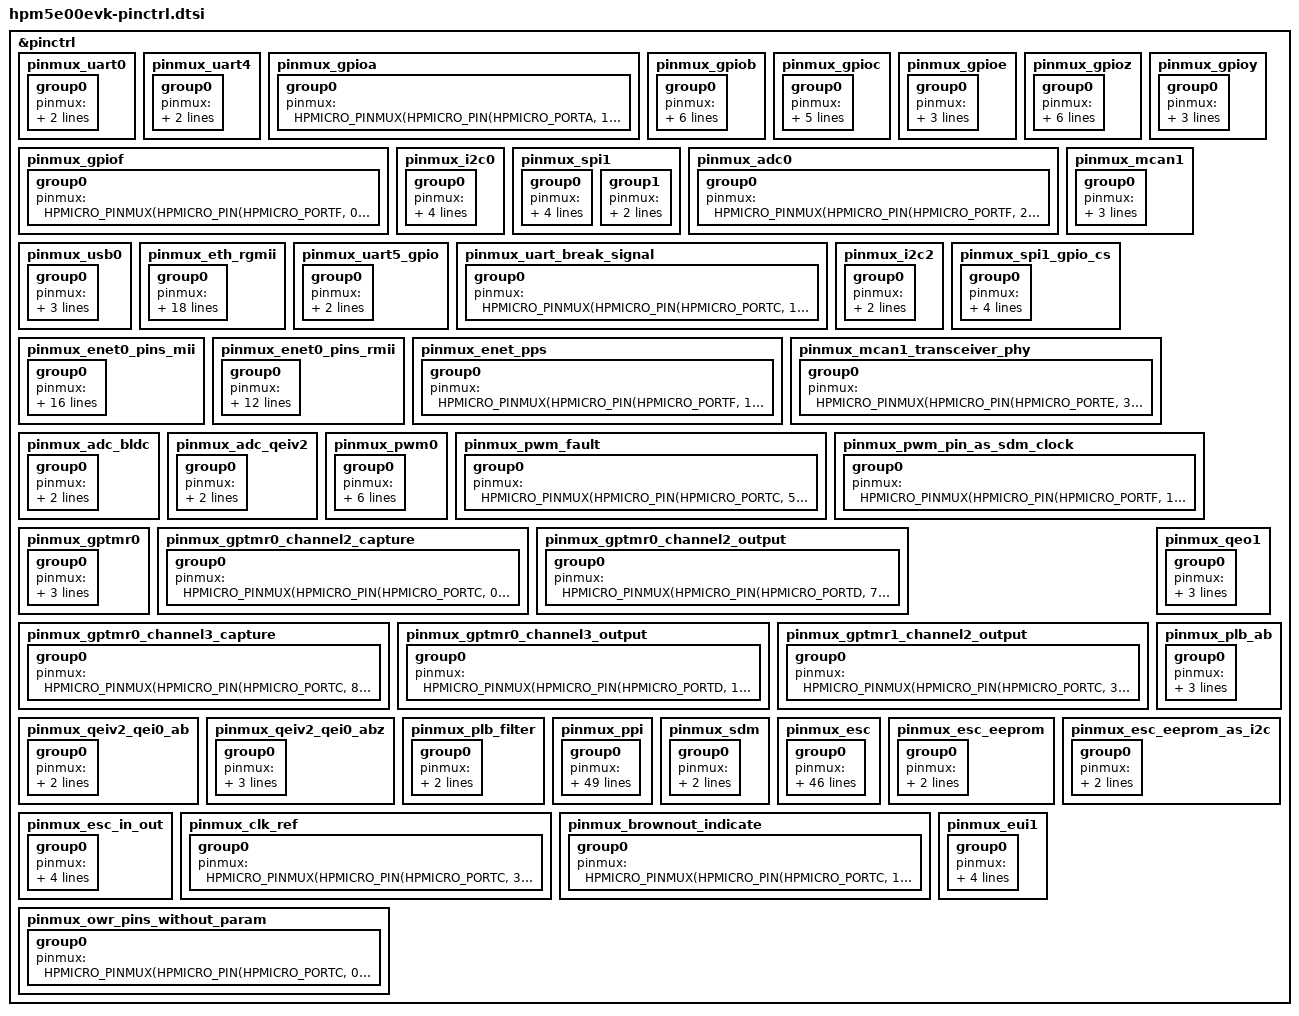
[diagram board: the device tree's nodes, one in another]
/*
* Copyright (c) 2026 HPMicro
* SPDX-License-Identifier: Apache-2.0
*/

#include "dt-bindings/pinctrl/hpmicro-pinctrl-common.h"

&pinctrl {
	pinmux_uart0: pinmux_uart0 {
		group0 {
			pinmux = <HPMICRO_PINMUX(HPMICRO_PIN(HPMICRO_PORTA, 0), IOC_TYPE_IOC, 0, 2)>,
				<HPMICRO_PINMUX(HPMICRO_PIN(HPMICRO_PORTA, 1), IOC_TYPE_IOC, 0, 2)>;
		};
	};

	pinmux_uart4: pinmux_uart4 {
		group0 {
			pinmux = <HPMICRO_PINMUX(HPMICRO_PIN(HPMICRO_PORTC, 16), IOC_TYPE_IOC, 0, 2)>,
				<HPMICRO_PINMUX(HPMICRO_PIN(HPMICRO_PORTC, 17), IOC_TYPE_IOC, 0, 2)>;
		};
	};

	pinmux_gpioa: pinmux_gpioa {
		group0 {
			pinmux = <HPMICRO_PINMUX(HPMICRO_PIN(HPMICRO_PORTA, 14), IOC_TYPE_IOC, 0, 0)>;
		};
	};

	pinmux_gpiob: pinmux_gpiob {
		group0 {
			pinmux = <HPMICRO_PINMUX(HPMICRO_PIN(HPMICRO_PORTB, 11), IOC_TYPE_IOC, 0, 0)>,
				<HPMICRO_PINMUX(HPMICRO_PIN(HPMICRO_PORTB, 12), IOC_TYPE_IOC, 0, 0)>,
				<HPMICRO_PINMUX(HPMICRO_PIN(HPMICRO_PORTB, 13), IOC_TYPE_IOC, 0, 0)>,
				<HPMICRO_PINMUX(HPMICRO_PIN(HPMICRO_PORTB, 8), IOC_TYPE_IOC, 0, 0)>,
				<HPMICRO_PINMUX(HPMICRO_PIN(HPMICRO_PORTB, 9), IOC_TYPE_IOC, 0, 0)>;
			bias-pull-down;
		};
	};

	pinmux_gpioc: pinmux_gpioc {
		group0 {
			pinmux = <HPMICRO_PINMUX(HPMICRO_PIN(HPMICRO_PORTC, 21), IOC_TYPE_IOC, 0, 0)>;
			bias-pull-up;
			input-enable;
			keeper-capability-disable;
			input-schmitt-enable;
		};
	};

	pinmux_gpioe: pinmux_gpioe {
		group0 {
			pinmux = <HPMICRO_PINMUX(HPMICRO_PIN(HPMICRO_PORTE, 4), IOC_TYPE_IOC, 0, 0)>,
				<HPMICRO_PINMUX(HPMICRO_PIN(HPMICRO_PORTE, 14), IOC_TYPE_IOC, 0, 0)>,
				<HPMICRO_PINMUX(HPMICRO_PIN(HPMICRO_PORTE, 15), IOC_TYPE_IOC, 0, 0)>;
		};
	};

	pinmux_gpiof: pinmux_gpiof {
		group0 {
			pinmux = <HPMICRO_PINMUX(HPMICRO_PIN(HPMICRO_PORTF, 0), IOC_TYPE_IOC, 0, 0)>;
		};
	};

	pinmux_gpioz: pinmux_gpioz {
		group0 {
			pinmux = <HPMICRO_PINMUX(HPMICRO_PIN(HPMICRO_PORTZ, 2), IOC_TYPE_IOC, 0, 0)>,
				<HPMICRO_PINMUX(HPMICRO_PIN(HPMICRO_PORTZ, 2), IOC_TYPE_BIOC, 0, 3)>,
				<HPMICRO_PINMUX(HPMICRO_PIN(HPMICRO_PORTZ, 3), IOC_TYPE_IOC, 0, 0)>,
				<HPMICRO_PINMUX(HPMICRO_PIN(HPMICRO_PORTZ, 3), IOC_TYPE_BIOC, 0, 3)>;
			bias-pull-up;
			input-enable;
		};
	};

	pinmux_gpioy: pinmux_gpioy {
		group0 {
			pinmux = <HPMICRO_PINMUX(HPMICRO_PIN(HPMICRO_PORTY, 5), IOC_TYPE_IOC, 0, 0)>,
				<HPMICRO_PINMUX(HPMICRO_PIN(HPMICRO_PORTY, 5), IOC_TYPE_BIOC, 0, 3)>;
			bias-pull-up;
		};
	};

	pinmux_i2c0: pinmux_i2c0 {
		group0 {
			pinmux = <HPMICRO_PINMUX(HPMICRO_PIN(HPMICRO_PORTC, 8), IOC_TYPE_IOC, 0, 4)>,
				<HPMICRO_PINMUX(HPMICRO_PIN(HPMICRO_PORTC, 9), IOC_TYPE_IOC, 0, 4)>;
			drive-open-drain;
			input-enable;
		};
	};

	pinmux_spi1: pinmux_spi1 {
		group0 {
			pinmux = <HPMICRO_PINMUX(HPMICRO_PIN(HPMICRO_PORTC, 10), IOC_TYPE_IOC, 0, 5)>,
				<HPMICRO_PINMUX(HPMICRO_PIN(HPMICRO_PORTC, 12), IOC_TYPE_IOC, 0, 5)>,
				<HPMICRO_PINMUX(HPMICRO_PIN(HPMICRO_PORTC, 13), IOC_TYPE_IOC, 0, 5)>;
			input-enable;
		};

		group1 {
			pinmux = <HPMICRO_PINMUX(HPMICRO_PIN(HPMICRO_PORTC, 11), IOC_TYPE_IOC, 0, 0)>;
			bias-pull-up;
		};
	};

	pinmux_adc0: pinmux_adc0 {
		group0 {
			pinmux = <HPMICRO_PINMUX(HPMICRO_PIN(HPMICRO_PORTF, 26), IOC_TYPE_IOC, 1, 0)>;
		};
	};

	pinmux_mcan1: pinmux_mcan1 {
		group0 {
			pinmux = <HPMICRO_PINMUX(HPMICRO_PIN(HPMICRO_PORTE, 5), IOC_TYPE_IOC, 0, 7)>,
				<HPMICRO_PINMUX(HPMICRO_PIN(HPMICRO_PORTE, 4), IOC_TYPE_IOC, 0, 7)>,
				<HPMICRO_PINMUX(HPMICRO_PIN(HPMICRO_PORTE, 3), IOC_TYPE_IOC, 0, 7)>;
		};
	};

	pinmux_usb0: pinmux_usb0 {
		group0 {
			pinmux = <HPMICRO_PINMUX(HPMICRO_PIN(HPMICRO_PORTF, 19), IOC_TYPE_IOC, 0, 24)>,
				<HPMICRO_PINMUX(HPMICRO_PIN(HPMICRO_PORTF, 22), IOC_TYPE_IOC, 0, 24)>,
				<HPMICRO_PINMUX(HPMICRO_PIN(HPMICRO_PORTF, 23), IOC_TYPE_IOC, 0, 24)>;
		};
	};

	pinmux_eth_rgmii: pinmux_eth_rgmii {
		group0 {
			pinmux = <HPMICRO_PINMUX(HPMICRO_PIN(HPMICRO_PORTF, 1), IOC_TYPE_IOC, 0, 18)>,
				<HPMICRO_PINMUX(HPMICRO_PIN(HPMICRO_PORTF, 0), IOC_TYPE_IOC, 0, 18)>,
				<HPMICRO_PINMUX(HPMICRO_PIN(HPMICRO_PORTB, 0), IOC_TYPE_IOC, 0, 18)>,
				<HPMICRO_PINMUX(HPMICRO_PIN(HPMICRO_PORTB, 1), IOC_TYPE_IOC, 0, 18)>,
				<HPMICRO_PINMUX(HPMICRO_PIN(HPMICRO_PORTB, 2), IOC_TYPE_IOC, 0, 18)>,
				<HPMICRO_PINMUX(HPMICRO_PIN(HPMICRO_PORTB, 3), IOC_TYPE_IOC, 0, 18)>,
				<HPMICRO_PINMUX(HPMICRO_PIN(HPMICRO_PORTB, 4), IOC_TYPE_IOC, 0, 18)>,
				<HPMICRO_PINMUX(HPMICRO_PIN(HPMICRO_PORTB, 5), IOC_TYPE_IOC, 0, 18)>,
				<HPMICRO_PINMUX(HPMICRO_PIN(HPMICRO_PORTB, 6), IOC_TYPE_IOC, 0, 18)>,
				<HPMICRO_PINMUX(HPMICRO_PIN(HPMICRO_PORTB, 7), IOC_TYPE_IOC, 0, 18)>,
				<HPMICRO_PINMUX(HPMICRO_PIN(HPMICRO_PORTB, 8), IOC_TYPE_IOC, 0, 18)>,
				<HPMICRO_PINMUX(HPMICRO_PIN(HPMICRO_PORTB, 9), IOC_TYPE_IOC, 0, 18)>,
				<HPMICRO_PINMUX(HPMICRO_PIN(HPMICRO_PORTB, 10), IOC_TYPE_IOC, 0, 18)>,
				<HPMICRO_PINMUX(HPMICRO_PIN(HPMICRO_PORTB, 11), IOC_TYPE_IOC, 0, 18)>;
			input-schmitt-enable;
			slew-rate = "fast";
			slew-pd = "100M";
			drive-strength = "r011";
		};
	};

	pinmux_uart5_gpio: pinmux_uart5_gpio {
		group0 {
			pinmux = <HPMICRO_PINMUX(HPMICRO_PIN(HPMICRO_PORTC, 22), IOC_TYPE_IOC, 0, 0)>,
				<HPMICRO_PINMUX(HPMICRO_PIN(HPMICRO_PORTC, 23), IOC_TYPE_IOC, 0, 0)>;
		};
	};

	pinmux_uart_break_signal: pinmux_uart_break_signal {
		group0 {
			pinmux = <HPMICRO_PINMUX(HPMICRO_PIN(HPMICRO_PORTC, 11), IOC_TYPE_IOC, 0, 0)>;
		};
	};

	pinmux_i2c2: pinmux_i2c2 {
		group0 {
			pinmux = <HPMICRO_PINMUX(HPMICRO_PIN(HPMICRO_PORTD, 3), IOC_TYPE_IOC, 0, 4)>,
				<HPMICRO_PINMUX(HPMICRO_PIN(HPMICRO_PORTD, 2), IOC_TYPE_IOC, 0, 4)>;
		};
	};

	pinmux_spi1_gpio_cs: pinmux_spi1_gpio_cs {
		group0 {
			pinmux = <HPMICRO_PINMUX(HPMICRO_PIN(HPMICRO_PORTC, 11), IOC_TYPE_IOC, 0, 0)>,
				<HPMICRO_PINMUX(HPMICRO_PIN(HPMICRO_PORTC, 10), IOC_TYPE_IOC, 0, 5)>,
				<HPMICRO_PINMUX(HPMICRO_PIN(HPMICRO_PORTC, 12), IOC_TYPE_IOC, 0, 5)>,
				<HPMICRO_PINMUX(HPMICRO_PIN(HPMICRO_PORTC, 13), IOC_TYPE_IOC, 0, 5)>;
		};
	};

	pinmux_enet0_pins_mii: pinmux_enet0_pins_mii {
		group0 {
			pinmux = <HPMICRO_PINMUX(HPMICRO_PIN(HPMICRO_PORTA, 9), IOC_TYPE_IOC, 0, 11)>,
				<HPMICRO_PINMUX(HPMICRO_PIN(HPMICRO_PORTB, 24), IOC_TYPE_IOC, 0, 0)>,
				<HPMICRO_PINMUX(HPMICRO_PIN(HPMICRO_PORTA, 30), IOC_TYPE_IOC, 0, 18)>,
				<HPMICRO_PINMUX(HPMICRO_PIN(HPMICRO_PORTA, 31), IOC_TYPE_IOC, 0, 18)>,
				<HPMICRO_PINMUX(HPMICRO_PIN(HPMICRO_PORTF, 2), IOC_TYPE_IOC, 0, 18)>,
				<HPMICRO_PINMUX(HPMICRO_PIN(HPMICRO_PORTF, 3), IOC_TYPE_IOC, 0, 18)>,
				<HPMICRO_PINMUX(HPMICRO_PIN(HPMICRO_PORTF, 4), IOC_TYPE_IOC, 0, 18)>,
				<HPMICRO_PINMUX(HPMICRO_PIN(HPMICRO_PORTF, 5), IOC_TYPE_IOC, 0, 18)>,
				<HPMICRO_PINMUX(HPMICRO_PIN(HPMICRO_PORTF, 6), IOC_TYPE_IOC, 0, 18)>,
				<HPMICRO_PINMUX(HPMICRO_PIN(HPMICRO_PORTF, 7), IOC_TYPE_IOC, 0, 18)>,
				<HPMICRO_PINMUX(HPMICRO_PIN(HPMICRO_PORTF, 8), IOC_TYPE_IOC, 0, 18)>,
				<HPMICRO_PINMUX(HPMICRO_PIN(HPMICRO_PORTF, 9), IOC_TYPE_IOC, 0, 18)>,
				<HPMICRO_PINMUX(HPMICRO_PIN(HPMICRO_PORTF, 10), IOC_TYPE_IOC, 0, 18)>,
				<HPMICRO_PINMUX(HPMICRO_PIN(HPMICRO_PORTF, 11), IOC_TYPE_IOC, 0, 18)>,
				<HPMICRO_PINMUX(HPMICRO_PIN(HPMICRO_PORTF, 12), IOC_TYPE_IOC, 0, 18)>,
				<HPMICRO_PINMUX(HPMICRO_PIN(HPMICRO_PORTF, 13), IOC_TYPE_IOC, 0, 18)>;
		};
	};

	pinmux_enet0_pins_rmii: pinmux_enet0_pins_rmii {
		group0 {
			pinmux = <HPMICRO_PINMUX(HPMICRO_PIN(HPMICRO_PORTA, 9), IOC_TYPE_IOC, 0, 11)>,
				<HPMICRO_PINMUX(HPMICRO_PIN(HPMICRO_PORTB, 24), IOC_TYPE_IOC, 0, 0)>,
				<HPMICRO_PINMUX(HPMICRO_PIN(HPMICRO_PORTF, 2), IOC_TYPE_IOC, 0, 18)>,
				<HPMICRO_PINMUX(HPMICRO_PIN(HPMICRO_PORTA, 30), IOC_TYPE_IOC, 0, 18)>,
				<HPMICRO_PINMUX(HPMICRO_PIN(HPMICRO_PORTA, 31), IOC_TYPE_IOC, 0, 18)>,
				<HPMICRO_PINMUX(HPMICRO_PIN(HPMICRO_PORTF, 3), IOC_TYPE_IOC, 0, 18)>,
				<HPMICRO_PINMUX(HPMICRO_PIN(HPMICRO_PORTF, 4), IOC_TYPE_IOC, 0, 18)>,
				<HPMICRO_PINMUX(HPMICRO_PIN(HPMICRO_PORTF, 7), IOC_TYPE_IOC, 0, 18)>,
				<HPMICRO_PINMUX(HPMICRO_PIN(HPMICRO_PORTF, 8), IOC_TYPE_IOC, 0, 18)>,
				<HPMICRO_PINMUX(HPMICRO_PIN(HPMICRO_PORTF, 9), IOC_TYPE_IOC, 0, 18)>,
				<HPMICRO_PINMUX(HPMICRO_PIN(HPMICRO_PORTF, 10), IOC_TYPE_IOC, 0, 18)>;
			input-enable;
		};
	};

	pinmux_enet_pps: pinmux_enet_pps {
		group0 {
			pinmux = <HPMICRO_PINMUX(HPMICRO_PIN(HPMICRO_PORTF, 18), IOC_TYPE_IOC, 0, 25)>;
		};
	};

	pinmux_mcan1_transceiver_phy: pinmux_mcan1_transceiver_phy {
		group0 {
			pinmux = <HPMICRO_PINMUX(HPMICRO_PIN(HPMICRO_PORTE, 3), IOC_TYPE_IOC, 0, 0)>;
		};
	};

	pinmux_adc_bldc: pinmux_adc_bldc {
		group0 {
			pinmux = <HPMICRO_PINMUX(HPMICRO_PIN(HPMICRO_PORTF, 28), IOC_TYPE_IOC, 1, 0)>,
				<HPMICRO_PINMUX(HPMICRO_PIN(HPMICRO_PORTF, 29), IOC_TYPE_IOC, 1, 0)>;
		};
	};

	pinmux_adc_qeiv2: pinmux_adc_qeiv2 {
		group0 {
			pinmux = <HPMICRO_PINMUX(HPMICRO_PIN(HPMICRO_PORTF, 30), IOC_TYPE_IOC, 1, 0)>,
				<HPMICRO_PINMUX(HPMICRO_PIN(HPMICRO_PORTF, 28), IOC_TYPE_IOC, 1, 0)>;
		};
	};

	pinmux_pwm0: pinmux_pwm0 {
		group0 {
			pinmux = <HPMICRO_PINMUX(HPMICRO_PIN(HPMICRO_PORTD, 0), IOC_TYPE_IOC, 0, 16)>,
				<HPMICRO_PINMUX(HPMICRO_PIN(HPMICRO_PORTD, 1), IOC_TYPE_IOC, 0, 16)>,
				<HPMICRO_PINMUX(HPMICRO_PIN(HPMICRO_PORTD, 2), IOC_TYPE_IOC, 0, 16)>,
				<HPMICRO_PINMUX(HPMICRO_PIN(HPMICRO_PORTD, 3), IOC_TYPE_IOC, 0, 16)>,
				<HPMICRO_PINMUX(HPMICRO_PIN(HPMICRO_PORTD, 4), IOC_TYPE_IOC, 0, 16)>,
				<HPMICRO_PINMUX(HPMICRO_PIN(HPMICRO_PORTD, 5), IOC_TYPE_IOC, 0, 16)>;
		};
	};

	pinmux_pwm_fault: pinmux_pwm_fault {
		group0 {
			pinmux = <HPMICRO_PINMUX(HPMICRO_PIN(HPMICRO_PORTC, 5), IOC_TYPE_IOC, 0, 17)>;
		};
	};

	pinmux_pwm_pin_as_sdm_clock: pinmux_pwm_pin_as_sdm_clock {
		group0 {
			pinmux = <HPMICRO_PINMUX(HPMICRO_PIN(HPMICRO_PORTF, 15), IOC_TYPE_IOC, 0, 16)>;
		};
	};

	pinmux_gptmr0: pinmux_gptmr0 {
		group0 {
			pinmux = <HPMICRO_PINMUX(HPMICRO_PIN(HPMICRO_PORTC, 0), IOC_TYPE_IOC, 0, 17)>,
				<HPMICRO_PINMUX(HPMICRO_PIN(HPMICRO_PORTD, 7), IOC_TYPE_IOC, 0, 17)>,
				<HPMICRO_PINMUX(HPMICRO_PIN(HPMICRO_PORTD, 15), IOC_TYPE_IOC, 0, 17)>;
		};
	};

	pinmux_gptmr0_channel2_capture: pinmux_gptmr0_channel2_capture {
		group0 {
			pinmux = <HPMICRO_PINMUX(HPMICRO_PIN(HPMICRO_PORTC, 0), IOC_TYPE_IOC, 0, 17)>;
		};
	};

	pinmux_gptmr0_channel2_output: pinmux_gptmr0_channel2_output {
		group0 {
			pinmux = <HPMICRO_PINMUX(HPMICRO_PIN(HPMICRO_PORTD, 7), IOC_TYPE_IOC, 0, 17)>;
		};
	};

	pinmux_gptmr0_channel3_capture: pinmux_gptmr0_channel3_capture {
		group0 {
			pinmux = <HPMICRO_PINMUX(HPMICRO_PIN(HPMICRO_PORTC, 8), IOC_TYPE_IOC, 0, 17)>;
		};
	};

	pinmux_gptmr0_channel3_output: pinmux_gptmr0_channel3_output {
		group0 {
			pinmux = <HPMICRO_PINMUX(HPMICRO_PIN(HPMICRO_PORTD, 15), IOC_TYPE_IOC, 0, 17)>;
		};
	};

	pinmux_gptmr1_channel2_output: pinmux_gptmr1_channel2_output {
		group0 {
			pinmux = <HPMICRO_PINMUX(HPMICRO_PIN(HPMICRO_PORTC, 3), IOC_TYPE_IOC, 0, 17)>;
		};
	};

	pinmux_qeo1: pinmux_qeo1 {
		group0 {
			pinmux = <HPMICRO_PINMUX(HPMICRO_PIN(HPMICRO_PORTC, 12), IOC_TYPE_IOC, 0, 21)>,
				<HPMICRO_PINMUX(HPMICRO_PIN(HPMICRO_PORTC, 13), IOC_TYPE_IOC, 0, 21)>,
				<HPMICRO_PINMUX(HPMICRO_PIN(HPMICRO_PORTC, 14), IOC_TYPE_IOC, 0, 21)>;
		};
	};

	pinmux_qeiv2_qei0_ab: pinmux_qeiv2_qei0_ab {
		group0 {
			pinmux = <HPMICRO_PINMUX(HPMICRO_PIN(HPMICRO_PORTC, 7), IOC_TYPE_IOC, 0, 20)>,
				<HPMICRO_PINMUX(HPMICRO_PIN(HPMICRO_PORTC, 6), IOC_TYPE_IOC, 0, 20)>;
		};
	};

	pinmux_qeiv2_qei0_abz: pinmux_qeiv2_qei0_abz {
		group0 {
			pinmux = <HPMICRO_PINMUX(HPMICRO_PIN(HPMICRO_PORTC, 7), IOC_TYPE_IOC, 0, 20)>,
				<HPMICRO_PINMUX(HPMICRO_PIN(HPMICRO_PORTC, 6), IOC_TYPE_IOC, 0, 20)>,
				<HPMICRO_PINMUX(HPMICRO_PIN(HPMICRO_PORTC, 5), IOC_TYPE_IOC, 0, 20)>;
		};
	};

	pinmux_plb_ab: pinmux_plb_ab {
		group0 {
			pinmux = <HPMICRO_PINMUX(HPMICRO_PIN(HPMICRO_PORTC, 5), IOC_TYPE_IOC, 0, 17)>,
				<HPMICRO_PINMUX(HPMICRO_PIN(HPMICRO_PORTC, 6), IOC_TYPE_IOC, 0, 17)>,
				<HPMICRO_PINMUX(HPMICRO_PIN(HPMICRO_PORTC, 7), IOC_TYPE_IOC, 0, 17)>;
		};
	};

	pinmux_plb_filter: pinmux_plb_filter {
		group0 {
			pinmux = <HPMICRO_PINMUX(HPMICRO_PIN(HPMICRO_PORTD, 2), IOC_TYPE_IOC, 0, 17)>,
				<HPMICRO_PINMUX(HPMICRO_PIN(HPMICRO_PORTD, 4), IOC_TYPE_IOC, 0, 17)>;
		};
	};

	pinmux_ppi: pinmux_ppi {
		group0 {
			pinmux = <HPMICRO_PINMUX(HPMICRO_PIN(HPMICRO_PORTD, 31), IOC_TYPE_IOC, 0, 13)>,
				<HPMICRO_PINMUX(HPMICRO_PIN(HPMICRO_PORTD, 30), IOC_TYPE_IOC, 0, 13)>,
				<HPMICRO_PINMUX(HPMICRO_PIN(HPMICRO_PORTD, 29), IOC_TYPE_IOC, 0, 13)>,
				<HPMICRO_PINMUX(HPMICRO_PIN(HPMICRO_PORTD, 28), IOC_TYPE_IOC, 0, 13)>,
				<HPMICRO_PINMUX(HPMICRO_PIN(HPMICRO_PORTD, 27), IOC_TYPE_IOC, 0, 13)>,
				<HPMICRO_PINMUX(HPMICRO_PIN(HPMICRO_PORTD, 26), IOC_TYPE_IOC, 0, 13)>,
				<HPMICRO_PINMUX(HPMICRO_PIN(HPMICRO_PORTD, 24), IOC_TYPE_IOC, 0, 13)>,
				<HPMICRO_PINMUX(HPMICRO_PIN(HPMICRO_PORTD, 25), IOC_TYPE_IOC, 0, 13)>,
				<HPMICRO_PINMUX(HPMICRO_PIN(HPMICRO_PORTD, 14), IOC_TYPE_IOC, 0, 13)>,
				<HPMICRO_PINMUX(HPMICRO_PIN(HPMICRO_PORTD, 17), IOC_TYPE_IOC, 0, 13)>,
				<HPMICRO_PINMUX(HPMICRO_PIN(HPMICRO_PORTD, 16), IOC_TYPE_IOC, 0, 13)>,
				<HPMICRO_PINMUX(HPMICRO_PIN(HPMICRO_PORTD, 19), IOC_TYPE_IOC, 0, 13)>,
				<HPMICRO_PINMUX(HPMICRO_PIN(HPMICRO_PORTD, 18), IOC_TYPE_IOC, 0, 13)>,
				<HPMICRO_PINMUX(HPMICRO_PIN(HPMICRO_PORTD, 21), IOC_TYPE_IOC, 0, 13)>,
				<HPMICRO_PINMUX(HPMICRO_PIN(HPMICRO_PORTD, 20), IOC_TYPE_IOC, 0, 13)>,
				<HPMICRO_PINMUX(HPMICRO_PIN(HPMICRO_PORTD, 22), IOC_TYPE_IOC, 0, 13)>,
				<HPMICRO_PINMUX(HPMICRO_PIN(HPMICRO_PORTC, 16), IOC_TYPE_IOC, 0, 13)>,
				<HPMICRO_PINMUX(HPMICRO_PIN(HPMICRO_PORTC, 17), IOC_TYPE_IOC, 0, 13)>,
				<HPMICRO_PINMUX(HPMICRO_PIN(HPMICRO_PORTC, 13), IOC_TYPE_IOC, 0, 13)>,
				<HPMICRO_PINMUX(HPMICRO_PIN(HPMICRO_PORTC, 14), IOC_TYPE_IOC, 0, 13)>,
				<HPMICRO_PINMUX(HPMICRO_PIN(HPMICRO_PORTC, 10), IOC_TYPE_IOC, 0, 13)>,
				<HPMICRO_PINMUX(HPMICRO_PIN(HPMICRO_PORTC, 11), IOC_TYPE_IOC, 0, 13)>,
				<HPMICRO_PINMUX(HPMICRO_PIN(HPMICRO_PORTC, 2), IOC_TYPE_IOC, 0, 13)>,
				<HPMICRO_PINMUX(HPMICRO_PIN(HPMICRO_PORTC, 9), IOC_TYPE_IOC, 0, 13)>,
				<HPMICRO_PINMUX(HPMICRO_PIN(HPMICRO_PORTC, 0), IOC_TYPE_IOC, 0, 13)>,
				<HPMICRO_PINMUX(HPMICRO_PIN(HPMICRO_PORTC, 1), IOC_TYPE_IOC, 0, 13)>,
				<HPMICRO_PINMUX(HPMICRO_PIN(HPMICRO_PORTC, 3), IOC_TYPE_IOC, 0, 13)>,
				<HPMICRO_PINMUX(HPMICRO_PIN(HPMICRO_PORTC, 4), IOC_TYPE_IOC, 0, 13)>,
				<HPMICRO_PINMUX(HPMICRO_PIN(HPMICRO_PORTC, 5), IOC_TYPE_IOC, 0, 13)>,
				<HPMICRO_PINMUX(HPMICRO_PIN(HPMICRO_PORTC, 6), IOC_TYPE_IOC, 0, 13)>,
				<HPMICRO_PINMUX(HPMICRO_PIN(HPMICRO_PORTC, 7), IOC_TYPE_IOC, 0, 13)>,
				<HPMICRO_PINMUX(HPMICRO_PIN(HPMICRO_PORTC, 8), IOC_TYPE_IOC, 0, 13)>,
				<HPMICRO_PINMUX(HPMICRO_PIN(HPMICRO_PORTD, 23), IOC_TYPE_IOC, 0, 13)>,
				<HPMICRO_PINMUX(HPMICRO_PIN(HPMICRO_PORTD, 15), IOC_TYPE_IOC, 0, 13)>,
				<HPMICRO_PINMUX(HPMICRO_PIN(HPMICRO_PORTC, 12), IOC_TYPE_IOC, 0, 13)>,
				<HPMICRO_PINMUX(HPMICRO_PIN(HPMICRO_PORTC, 15), IOC_TYPE_IOC, 0, 13)>,
				<HPMICRO_PINMUX(HPMICRO_PIN(HPMICRO_PORTC, 30), IOC_TYPE_IOC, 0, 13)>,
				<HPMICRO_PINMUX(HPMICRO_PIN(HPMICRO_PORTC, 31), IOC_TYPE_IOC, 0, 13)>,
				<HPMICRO_PINMUX(HPMICRO_PIN(HPMICRO_PORTD, 11), IOC_TYPE_IOC, 0, 13)>,
				<HPMICRO_PINMUX(HPMICRO_PIN(HPMICRO_PORTD, 8), IOC_TYPE_IOC, 0, 13)>,
				<HPMICRO_PINMUX(HPMICRO_PIN(HPMICRO_PORTC, 27), IOC_TYPE_IOC, 0, 13)>,
				<HPMICRO_PINMUX(HPMICRO_PIN(HPMICRO_PORTD, 10), IOC_TYPE_IOC, 0, 13)>,
				<HPMICRO_PINMUX(HPMICRO_PIN(HPMICRO_PORTC, 22), IOC_TYPE_IOC, 0, 13)>,
				<HPMICRO_PINMUX(HPMICRO_PIN(HPMICRO_PORTD, 7), IOC_TYPE_IOC, 0, 13)>,
				<HPMICRO_PINMUX(HPMICRO_PIN(HPMICRO_PORTE, 0), IOC_TYPE_IOC, 0, 13)>,
				<HPMICRO_PINMUX(HPMICRO_PIN(HPMICRO_PORTE, 1), IOC_TYPE_IOC, 0, 13)>,
				<HPMICRO_PINMUX(HPMICRO_PIN(HPMICRO_PORTE, 2), IOC_TYPE_IOC, 0, 13)>,
				<HPMICRO_PINMUX(HPMICRO_PIN(HPMICRO_PORTE, 3), IOC_TYPE_IOC, 0, 13)>,
				<HPMICRO_PINMUX(HPMICRO_PIN(HPMICRO_PORTC, 29), IOC_TYPE_IOC, 0, 13)>;
		};
	};

	pinmux_sdm: pinmux_sdm {
		group0 {
			pinmux = <HPMICRO_PINMUX(HPMICRO_PIN(HPMICRO_PORTF, 17), IOC_TYPE_IOC, 0, 23)>,
				<HPMICRO_PINMUX(HPMICRO_PIN(HPMICRO_PORTF, 16), IOC_TYPE_IOC, 0, 23)>;
		};
	};

	pinmux_esc: pinmux_esc {
		group0 {
			pinmux = <HPMICRO_PINMUX(HPMICRO_PIN(HPMICRO_PORTA, 9), IOC_TYPE_IOC, 0, 11)>,
				<HPMICRO_PINMUX(HPMICRO_PIN(HPMICRO_PORTA, 30), IOC_TYPE_IOC, 0, 11)>,
				<HPMICRO_PINMUX(HPMICRO_PIN(HPMICRO_PORTA, 31), IOC_TYPE_IOC, 0, 11)>,
				<HPMICRO_PINMUX(HPMICRO_PIN(HPMICRO_PORTB, 24), IOC_TYPE_IOC, 0, 0)>,
				<HPMICRO_PINMUX(HPMICRO_PIN(HPMICRO_PORTC, 20), IOC_TYPE_IOC, 0, 18)>,
				<HPMICRO_PINMUX(HPMICRO_PIN(HPMICRO_PORTB, 25), IOC_TYPE_IOC, 0, 11)>,
				<HPMICRO_PINMUX(HPMICRO_PIN(HPMICRO_PORTE, 2), IOC_TYPE_IOC, 0, 11)>,
				<HPMICRO_PINMUX(HPMICRO_PIN(HPMICRO_PORTA, 24), IOC_TYPE_IOC, 0, 11)>,
				<HPMICRO_PINMUX(HPMICRO_PIN(HPMICRO_PORTA, 29), IOC_TYPE_IOC, 0, 11)>,
				<HPMICRO_PINMUX(HPMICRO_PIN(HPMICRO_PORTA, 25), IOC_TYPE_IOC, 0, 11)>,
				<HPMICRO_PINMUX(HPMICRO_PIN(HPMICRO_PORTA, 26), IOC_TYPE_IOC, 0, 11)>,
				<HPMICRO_PINMUX(HPMICRO_PIN(HPMICRO_PORTA, 27), IOC_TYPE_IOC, 0, 11)>,
				<HPMICRO_PINMUX(HPMICRO_PIN(HPMICRO_PORTA, 28), IOC_TYPE_IOC, 0, 11)>,
				<HPMICRO_PINMUX(HPMICRO_PIN(HPMICRO_PORTA, 21), IOC_TYPE_IOC, 0, 11)>,
				<HPMICRO_PINMUX(HPMICRO_PIN(HPMICRO_PORTA, 16), IOC_TYPE_IOC, 0, 11)>,
				<HPMICRO_PINMUX(HPMICRO_PIN(HPMICRO_PORTA, 23), IOC_TYPE_IOC, 0, 11)>,
				<HPMICRO_PINMUX(HPMICRO_PIN(HPMICRO_PORTA, 17), IOC_TYPE_IOC, 0, 11)>,
				<HPMICRO_PINMUX(HPMICRO_PIN(HPMICRO_PORTA, 18), IOC_TYPE_IOC, 0, 11)>,
				<HPMICRO_PINMUX(HPMICRO_PIN(HPMICRO_PORTA, 19), IOC_TYPE_IOC, 0, 11)>,
				<HPMICRO_PINMUX(HPMICRO_PIN(HPMICRO_PORTA, 20), IOC_TYPE_IOC, 0, 11)>,
				<HPMICRO_PINMUX(HPMICRO_PIN(HPMICRO_PORTF, 2), IOC_TYPE_IOC, 0, 11)>,
				<HPMICRO_PINMUX(HPMICRO_PIN(HPMICRO_PORTF, 7), IOC_TYPE_IOC, 0, 11)>,
				<HPMICRO_PINMUX(HPMICRO_PIN(HPMICRO_PORTF, 3), IOC_TYPE_IOC, 0, 11)>,
				<HPMICRO_PINMUX(HPMICRO_PIN(HPMICRO_PORTF, 4), IOC_TYPE_IOC, 0, 11)>,
				<HPMICRO_PINMUX(HPMICRO_PIN(HPMICRO_PORTF, 5), IOC_TYPE_IOC, 0, 11)>,
				<HPMICRO_PINMUX(HPMICRO_PIN(HPMICRO_PORTF, 6), IOC_TYPE_IOC, 0, 11)>,
				<HPMICRO_PINMUX(HPMICRO_PIN(HPMICRO_PORTF, 13), IOC_TYPE_IOC, 0, 11)>,
				<HPMICRO_PINMUX(HPMICRO_PIN(HPMICRO_PORTF, 8), IOC_TYPE_IOC, 0, 11)>,
				<HPMICRO_PINMUX(HPMICRO_PIN(HPMICRO_PORTF, 14), IOC_TYPE_IOC, 0, 11)>,
				<HPMICRO_PINMUX(HPMICRO_PIN(HPMICRO_PORTF, 9), IOC_TYPE_IOC, 0, 11)>,
				<HPMICRO_PINMUX(HPMICRO_PIN(HPMICRO_PORTF, 10), IOC_TYPE_IOC, 0, 11)>,
				<HPMICRO_PINMUX(HPMICRO_PIN(HPMICRO_PORTF, 11), IOC_TYPE_IOC, 0, 11)>,
				<HPMICRO_PINMUX(HPMICRO_PIN(HPMICRO_PORTF, 12), IOC_TYPE_IOC, 0, 11)>,
				<HPMICRO_PINMUX(HPMICRO_PIN(HPMICRO_PORTD, 16), IOC_TYPE_IOC, 0, 27)>,
				<HPMICRO_PINMUX(HPMICRO_PIN(HPMICRO_PORTD, 17), IOC_TYPE_IOC, 0, 27)>,
				<HPMICRO_PINMUX(HPMICRO_PIN(HPMICRO_PORTD, 18), IOC_TYPE_IOC, 0, 27)>,
				<HPMICRO_PINMUX(HPMICRO_PIN(HPMICRO_PORTD, 19), IOC_TYPE_IOC, 0, 27)>,
				<HPMICRO_PINMUX(HPMICRO_PIN(HPMICRO_PORTD, 20), IOC_TYPE_IOC, 0, 27)>,
				<HPMICRO_PINMUX(HPMICRO_PIN(HPMICRO_PORTD, 21), IOC_TYPE_IOC, 0, 27)>,
				<HPMICRO_PINMUX(HPMICRO_PIN(HPMICRO_PORTD, 22), IOC_TYPE_IOC, 0, 27)>,
				<HPMICRO_PINMUX(HPMICRO_PIN(HPMICRO_PORTD, 23), IOC_TYPE_IOC, 0, 27)>,
				<HPMICRO_PINMUX(HPMICRO_PIN(HPMICRO_PORTD, 24), IOC_TYPE_IOC, 0, 27)>,
				<HPMICRO_PINMUX(HPMICRO_PIN(HPMICRO_PORTD, 25), IOC_TYPE_IOC, 0, 27)>,
				<HPMICRO_PINMUX(HPMICRO_PIN(HPMICRO_PORTD, 26), IOC_TYPE_IOC, 0, 27)>,
				<HPMICRO_PINMUX(HPMICRO_PIN(HPMICRO_PORTD, 27), IOC_TYPE_IOC, 0, 27)>,
				<HPMICRO_PINMUX(HPMICRO_PIN(HPMICRO_PORTD, 28), IOC_TYPE_IOC, 0, 27)>;
		};
	};

	pinmux_esc_eeprom: pinmux_esc_eeprom {
		group0 {
			pinmux = <HPMICRO_PINMUX(HPMICRO_PIN(HPMICRO_PORTD, 8), IOC_TYPE_IOC, 0, 18)>,
				<HPMICRO_PINMUX(HPMICRO_PIN(HPMICRO_PORTD, 9), IOC_TYPE_IOC, 0, 18)>;
		};
	};

	pinmux_esc_eeprom_as_i2c: pinmux_esc_eeprom_as_i2c {
		group0 {
			pinmux = <HPMICRO_PINMUX(HPMICRO_PIN(HPMICRO_PORTD, 8), IOC_TYPE_IOC, 0, 4)>,
				<HPMICRO_PINMUX(HPMICRO_PIN(HPMICRO_PORTD, 9), IOC_TYPE_IOC, 0, 4)>;
		};
	};

	pinmux_esc_in_out: pinmux_esc_in_out {
		group0 {
			pinmux = <HPMICRO_PINMUX(HPMICRO_PIN(HPMICRO_PORTD, 6), IOC_TYPE_IOC, 0, 0)>,
				<HPMICRO_PINMUX(HPMICRO_PIN(HPMICRO_PORTD, 12), IOC_TYPE_IOC, 0, 0)>,
				<HPMICRO_PINMUX(HPMICRO_PIN(HPMICRO_PORTC, 23), IOC_TYPE_IOC, 0, 0)>,
				<HPMICRO_PINMUX(HPMICRO_PIN(HPMICRO_PORTC, 24), IOC_TYPE_IOC, 0, 0)>;
		};
	};

	pinmux_clk_ref: pinmux_clk_ref {
		group0 {
			pinmux = <HPMICRO_PINMUX(HPMICRO_PIN(HPMICRO_PORTC, 30), IOC_TYPE_IOC, 0, 24)>;
		};
	};

	pinmux_brownout_indicate: pinmux_brownout_indicate {
		group0 {
			pinmux = <HPMICRO_PINMUX(HPMICRO_PIN(HPMICRO_PORTC, 16), IOC_TYPE_IOC, 0, 0)>;
		};
	};

	pinmux_eui1: pinmux_eui1 {
		group0 {
			pinmux = <HPMICRO_PINMUX(HPMICRO_PIN(HPMICRO_PORTB, 26), IOC_TYPE_IOC, 0, 26)>,
				<HPMICRO_PINMUX(HPMICRO_PIN(HPMICRO_PORTB, 27), IOC_TYPE_IOC, 0, 26)>,
				<HPMICRO_PINMUX(HPMICRO_PIN(HPMICRO_PORTB, 28), IOC_TYPE_IOC, 0, 26)>,
				<HPMICRO_PINMUX(HPMICRO_PIN(HPMICRO_PORTB, 29), IOC_TYPE_IOC, 0, 26)>;
		};
	};

	pinmux_owr_pins_without_param: pinmux_owr_pins_without_param {
		group0 {
			pinmux = <HPMICRO_PINMUX(HPMICRO_PIN(HPMICRO_PORTC, 0), IOC_TYPE_IOC, 0, 26)>;
		};
	};
};
